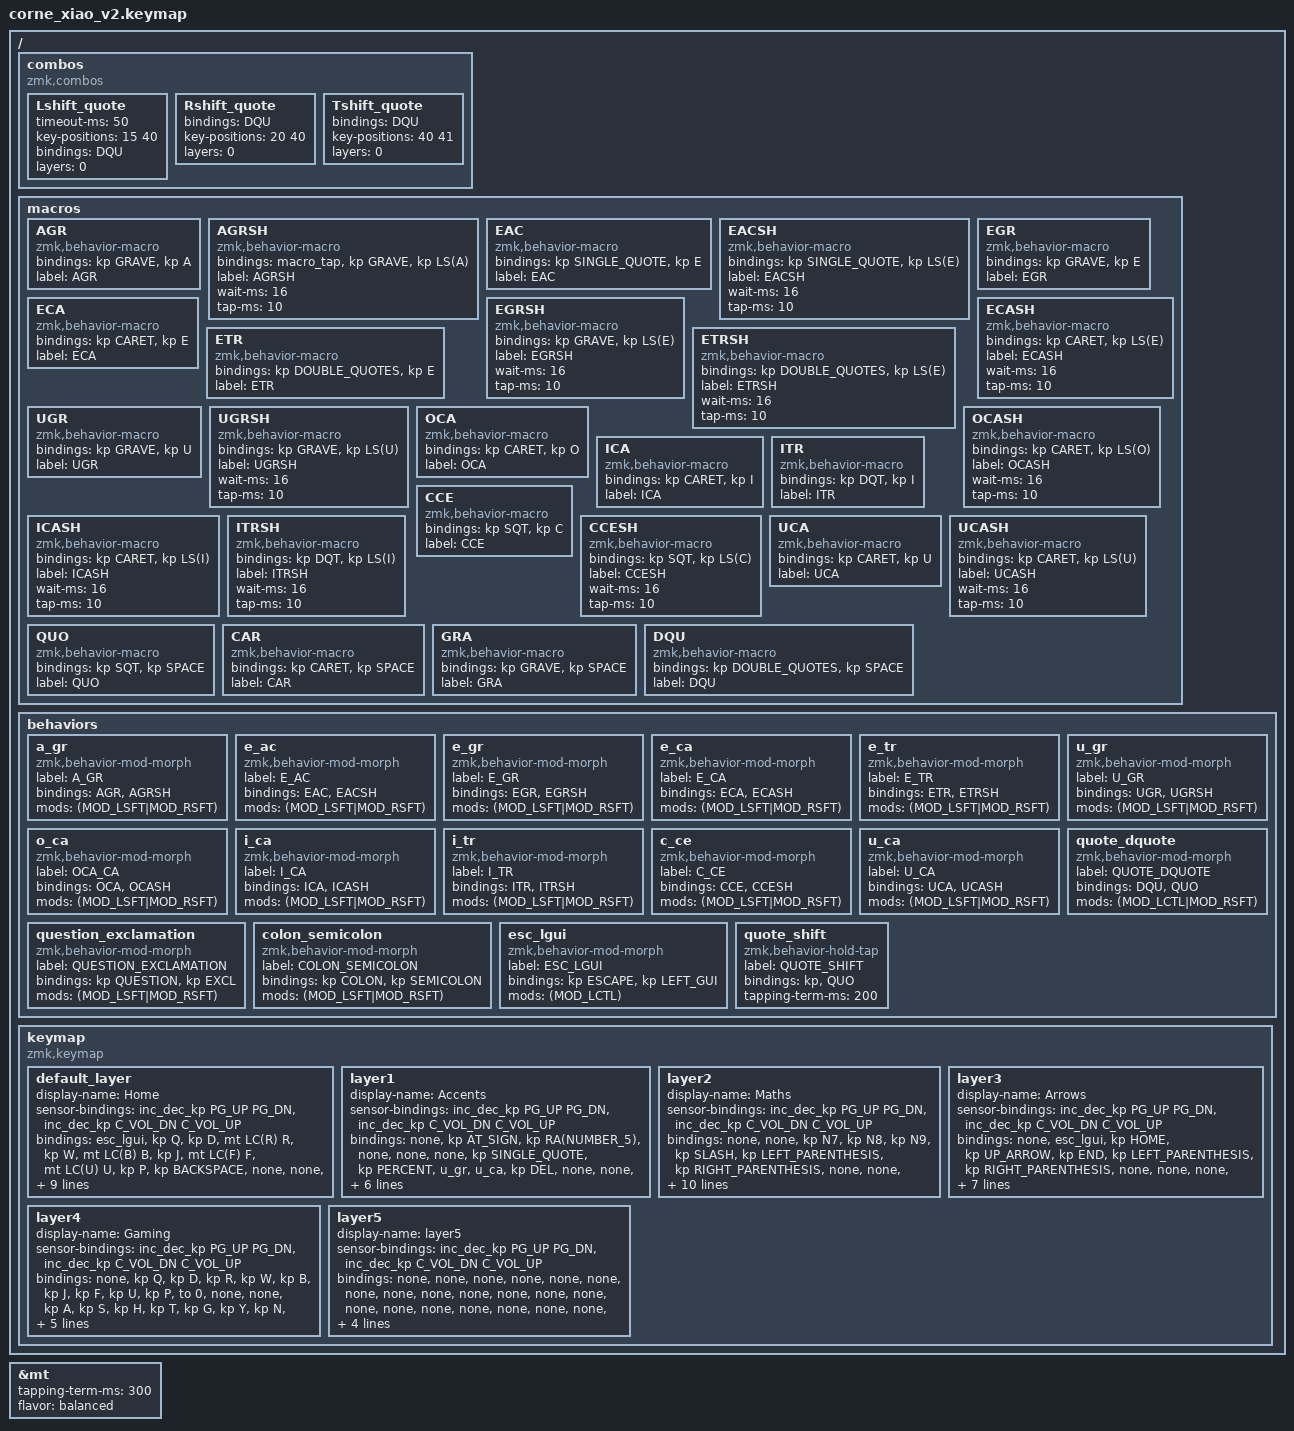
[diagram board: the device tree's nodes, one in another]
#include <behaviors/rgbled_widget.dtsi>  // needed to use the behaviors
#include <behaviors.dtsi>
#include <dt-bindings/zmk/keys.h>

// &ind_bat  indicate battery level
// &ind_con  indicate connectivity status

&mt {
    tapping-term-ms = <300>;
    flavor = "balanced";
};

/ {
    combos {
        compatible = "zmk,combos";

        Lshift_quote {
            timeout-ms = <50>;
            key-positions = <15 40>;
            bindings = <&DQU>;
            layers = <0>;
        };

        Rshift_quote {
            bindings = <&DQU>;
            key-positions = <20 40>;
            layers = <0>;
        };

        Tshift_quote {
            bindings = <&DQU>;
            key-positions = <40 41>;
            layers = <0>;
        };
    };
};

/ {
    macros {
        AGR: AGR {
            compatible = "zmk,behavior-macro";
            #binding-cells = <0>;
            bindings = <&kp GRAVE &kp A>;
            label = "AGR";
        };

        AGRSH: AGRSH {
            compatible = "zmk,behavior-macro";
            #binding-cells = <0>;
            bindings = <&macro_tap>, <&kp GRAVE &kp LS(A)>;

            label = "AGRSH";
            wait-ms = <16>;
            tap-ms = <10>;
        };

        EAC: EAC {
            compatible = "zmk,behavior-macro";
            #binding-cells = <0>;
            bindings = <&kp SINGLE_QUOTE &kp E>;
            label = "EAC";
        };

        EACSH: EACSH {
            compatible = "zmk,behavior-macro";
            #binding-cells = <0>;
            bindings = <&kp SINGLE_QUOTE &kp LS(E)>;
            label = "EACSH";
            wait-ms = <16>;
            tap-ms = <10>;
        };

        EGR: EGR {
            compatible = "zmk,behavior-macro";
            #binding-cells = <0>;
            bindings = <&kp GRAVE &kp E>;
            label = "EGR";
        };

        EGRSH: EGRSH {
            compatible = "zmk,behavior-macro";
            #binding-cells = <0>;
            bindings = <&kp GRAVE &kp LS(E)>;
            label = "EGRSH";
            wait-ms = <16>;
            tap-ms = <10>;
        };

        ECA: ECA {
            compatible = "zmk,behavior-macro";
            #binding-cells = <0>;
            bindings = <&kp CARET &kp E>;
            label = "ECA";
        };

        ECASH: ECASH {
            compatible = "zmk,behavior-macro";
            #binding-cells = <0>;
            bindings = <&kp CARET &kp LS(E)>;
            label = "ECASH";
            wait-ms = <16>;
            tap-ms = <10>;
        };

        ETR: ETR {
            compatible = "zmk,behavior-macro";
            #binding-cells = <0>;
            bindings = <&kp DOUBLE_QUOTES &kp E>;
            label = "ETR";
        };

        ETRSH: ETRSH {
            compatible = "zmk,behavior-macro";
            #binding-cells = <0>;
            bindings = <&kp DOUBLE_QUOTES &kp LS(E)>;
            label = "ETRSH";
            wait-ms = <16>;
            tap-ms = <10>;
        };

        UGR: UGR {
            compatible = "zmk,behavior-macro";
            #binding-cells = <0>;
            bindings = <&kp GRAVE &kp U>;
            label = "UGR";
        };

        UGRSH: UGRSH {
            compatible = "zmk,behavior-macro";
            #binding-cells = <0>;
            bindings = <&kp GRAVE &kp LS(U)>;
            label = "UGRSH";
            wait-ms = <16>;
            tap-ms = <10>;
        };

        OCA: OCA {
            compatible = "zmk,behavior-macro";
            #binding-cells = <0>;
            bindings = <&kp CARET &kp O>;
            label = "OCA";
        };

        OCASH: OCASH {
            compatible = "zmk,behavior-macro";
            #binding-cells = <0>;
            bindings = <&kp CARET &kp LS(O)>;
            label = "OCASH";
            wait-ms = <16>;
            tap-ms = <10>;
        };

        ICA: ICA {
            compatible = "zmk,behavior-macro";
            #binding-cells = <0>;
            bindings = <&kp CARET &kp I>;
            label = "ICA";
        };

        ICASH: ICASH {
            compatible = "zmk,behavior-macro";
            #binding-cells = <0>;
            bindings = <&kp CARET &kp LS(I)>;
            label = "ICASH";
            wait-ms = <16>;
            tap-ms = <10>;
        };

        ITR: ITR {
            compatible = "zmk,behavior-macro";
            #binding-cells = <0>;
            bindings = <&kp DQT &kp I>;
            label = "ITR";
        };

        ITRSH: ITRSH {
            compatible = "zmk,behavior-macro";
            #binding-cells = <0>;
            bindings = <&kp DQT &kp LS(I)>;
            label = "ITRSH";
            wait-ms = <16>;
            tap-ms = <10>;
        };

        CCE: CCE {
            compatible = "zmk,behavior-macro";
            #binding-cells = <0>;
            bindings = <&kp SQT &kp C>;
            label = "CCE";
        };

        CCESH: CCESH {
            compatible = "zmk,behavior-macro";
            #binding-cells = <0>;
            bindings = <&kp SQT &kp LS(C)>;
            label = "CCESH";
            wait-ms = <16>;
            tap-ms = <10>;
        };

        UCA: UCA {
            compatible = "zmk,behavior-macro";
            #binding-cells = <0>;
            bindings = <&kp CARET &kp U>;
            label = "UCA";
        };

        UCASH: UCASH {
            compatible = "zmk,behavior-macro";
            #binding-cells = <0>;
            bindings = <&kp CARET &kp LS(U)>;
            label = "UCASH";
            wait-ms = <16>;
            tap-ms = <10>;
        };

        QUO: QUO {
            compatible = "zmk,behavior-macro";
            #binding-cells = <0>;
            bindings = <&kp SQT &kp SPACE>;
            label = "QUO";
        };

        CAR: CAR {
            compatible = "zmk,behavior-macro";
            #binding-cells = <0>;
            bindings = <&kp CARET &kp SPACE>;
            label = "CAR";
        };

        GRA: GRA {
            compatible = "zmk,behavior-macro";
            #binding-cells = <0>;
            bindings = <&kp GRAVE &kp SPACE>;
            label = "GRA";
        };

        DQU: DQU {
            compatible = "zmk,behavior-macro";
            #binding-cells = <0>;
            bindings = <&kp DOUBLE_QUOTES &kp SPACE>;
            label = "DQU";
        };
    };

    behaviors {
        a_gr: a_gr {
            compatible = "zmk,behavior-mod-morph";
            label = "A_GR";
            bindings = <&AGR>, <&AGRSH>;

            #binding-cells = <0>;
            mods = <(MOD_LSFT|MOD_RSFT)>;
        };

        e_ac: e_ac {
            compatible = "zmk,behavior-mod-morph";
            label = "E_AC";
            bindings = <&EAC>, <&EACSH>;

            #binding-cells = <0>;
            mods = <(MOD_LSFT|MOD_RSFT)>;
        };

        e_gr: e_gr {
            compatible = "zmk,behavior-mod-morph";
            label = "E_GR";
            bindings = <&EGR>, <&EGRSH>;

            #binding-cells = <0>;
            mods = <(MOD_LSFT|MOD_RSFT)>;
        };

        e_ca: e_ca {
            compatible = "zmk,behavior-mod-morph";
            label = "E_CA";
            bindings = <&ECA>, <&ECASH>;

            #binding-cells = <0>;
            mods = <(MOD_LSFT|MOD_RSFT)>;
        };

        e_tr: e_tr {
            compatible = "zmk,behavior-mod-morph";
            label = "E_TR";
            bindings = <&ETR>, <&ETRSH>;

            #binding-cells = <0>;
            mods = <(MOD_LSFT|MOD_RSFT)>;
        };

        u_gr: u_gr {
            compatible = "zmk,behavior-mod-morph";
            label = "U_GR";
            bindings = <&UGR>, <&UGRSH>;

            #binding-cells = <0>;
            mods = <(MOD_LSFT|MOD_RSFT)>;
        };

        o_ca: o_ca {
            compatible = "zmk,behavior-mod-morph";
            label = "OCA_CA";
            bindings = <&OCA>, <&OCASH>;

            #binding-cells = <0>;
            mods = <(MOD_LSFT|MOD_RSFT)>;
        };

        i_ca: i_ca {
            compatible = "zmk,behavior-mod-morph";
            label = "I_CA";
            bindings = <&ICA>, <&ICASH>;

            #binding-cells = <0>;
            mods = <(MOD_LSFT|MOD_RSFT)>;
        };

        i_tr: i_tr {
            compatible = "zmk,behavior-mod-morph";
            label = "I_TR";
            bindings = <&ITR>, <&ITRSH>;

            #binding-cells = <0>;
            mods = <(MOD_LSFT|MOD_RSFT)>;
        };

        c_ce: c_ce {
            compatible = "zmk,behavior-mod-morph";
            label = "C_CE";
            bindings = <&CCE>, <&CCESH>;

            #binding-cells = <0>;
            mods = <(MOD_LSFT|MOD_RSFT)>;
        };

        u_ca: u_ca {
            compatible = "zmk,behavior-mod-morph";
            label = "U_CA";
            bindings = <&UCA>, <&UCASH>;

            #binding-cells = <0>;
            mods = <(MOD_LSFT|MOD_RSFT)>;
        };

        question_exclamation: question_exclamation {
            compatible = "zmk,behavior-mod-morph";
            label = "QUESTION_EXCLAMATION";
            bindings = <&kp QUESTION>, <&kp EXCL>;

            #binding-cells = <0>;
            mods = <(MOD_LSFT|MOD_RSFT)>;
        };

        colon_semicolon: colon_semicolon {
            compatible = "zmk,behavior-mod-morph";
            label = "COLON_SEMICOLON";
            bindings = <&kp COLON>, <&kp SEMICOLON>;

            #binding-cells = <0>;
            mods = <(MOD_LSFT|MOD_RSFT)>;
        };

        esc_lgui: esc_lgui {
            compatible = "zmk,behavior-mod-morph";
            label = "ESC_LGUI";
            bindings = <&kp ESCAPE>, <&kp LEFT_GUI>;

            #binding-cells = <0>;
            mods = <(MOD_LCTL)>;
        };

        quote_dquote: quote_dquote {
            compatible = "zmk,behavior-mod-morph";
            label = "QUOTE_DQUOTE";
            bindings = <&DQU>, <&QUO>;

            #binding-cells = <0>;
            mods = <(MOD_LCTL|MOD_RSFT)>;
        };

        quote_shift: quote_shift {
            compatible = "zmk,behavior-hold-tap";
            label = "QUOTE_SHIFT";
            bindings = <&kp>, <&QUO>;

            #binding-cells = <2>;
            tapping-term-ms = <200>;
        };
    };

    keymap {
        compatible = "zmk,keymap";

        default_layer {
            display-name = "Home";
            sensor-bindings = <&inc_dec_kp PG_UP PG_DN &inc_dec_kp C_VOL_DN C_VOL_UP>;
            bindings = <
&esc_lgui  &kp Q  &kp D  &mt LC(R) R  &kp W  &mt LC(B) B  &kp J  &mt LC(F) F  &mt LC(U) U  &kp P  &kp BACKSPACE  &none  &none  &mt LC(A) A  &mt LC(S) S  &mt LEFT_SHIFT H  &mt LEFT_CONTROL T  &mt G G  &kp Y  &mt LCTRL N  &mt RIGHT_SHIFT E  &kp O  &mt LC(I) I  &question_exclamation  &none  &mt LC(Z) Z  &mt LC(X) X  &kp M  &mt LC(C) C  &mt LC(V) V  &none  &kp C_MUTE  &kp K  &kp L  &kp COMMA  &colon_semicolon  &kp EQUAL  &none  &lt 2 MINUS  &lt 3 SPACE  &quote_shift LEFT_SHIFT 0  &mt LEFT_ALT PERIOD  &kp ENTER  &lt 1 DOT
            >;
        };

        layer1 {
            display-name = "Accents";
            sensor-bindings = <&inc_dec_kp PG_UP PG_DN &inc_dec_kp C_VOL_DN C_VOL_UP>;
            bindings = <
&none  &kp AT_SIGN  &kp RA(NUMBER_5)  &none  &none  &none  &kp SINGLE_QUOTE  &kp PERCENT  &u_gr  &u_ca  &kp DEL  &none  &none  &a_gr  &kp DOLLAR  &kp HASH  &none  &none  &kp CARET  &kp TILDE  &e_ac  &o_ca  &i_ca  &none  &none  &kp AMPERSAND  &none  &none  &c_ce  &none  &none  &none  &kp GRAVE  &e_ca  &e_gr  &e_tr  &i_tr  &none  &none  &none  &none  &none  &none  &none
            >;
        };

        layer2 {
            display-name = "Maths";
            sensor-bindings = <&inc_dec_kp PG_UP PG_DN &inc_dec_kp C_VOL_DN C_VOL_UP>;
            bindings = <
&none  &none  &kp N7  &kp N8  &kp N9  &kp SLASH  &kp LEFT_PARENTHESIS  &kp RIGHT_PARENTHESIS  &none  &none  &kp BACKSPACE  &none  &none  &none  &kp NUMBER_4  &kp N5  &kp NUMBER_6  &kp ASTERISK  &kp LEFT_BRACKET  &kp RIGHT_BRACKET  &kp SLASH  &kp PIPE  &kp NON_US_BACKSLASH  &none  &none  &kp N0  &kp NUMBER_1  &kp NUMBER_2  &kp NUMBER_3  &kp MINUS  &none  &none  &kp LEFT_BRACE  &kp RIGHT_BRACE  &none  &kp TILDE  &none  &none  &none  &kp PLUS  &kp EQUAL  &kp RET  &kp LESS_THAN  &kp GREATER_THAN
            >;
        };

        layer3 {
            display-name = "Arrows";
            sensor-bindings = <&inc_dec_kp PG_UP PG_DN &inc_dec_kp C_VOL_DN C_VOL_UP>;
            bindings = <
&none  &esc_lgui  &kp HOME  &kp UP_ARROW  &kp END  &kp LEFT_PARENTHESIS  &kp RIGHT_PARENTHESIS  &none  &none  &none  &to 4  &none  &none  &kp TAB  &kp LEFT_ARROW  &kp DOWN  &kp RIGHT  &kp QUESTION  &kp EXCL  &kp LCTRL  &kp LEFT_SHIFT  &none  &ind_bat  &none  &none  &kp LEFT_GUI  &kp LC(LEFT_ARROW)  &none  &kp LC(RIGHT)  &none  &none  &none  &none  &none  &none  &none  &none  &none  &none  &trans  &trans  &none  &none  &none
            >;
        };

        layer4 {
            display-name = "Gaming";
            sensor-bindings = <&inc_dec_kp PG_UP PG_DN &inc_dec_kp C_VOL_DN C_VOL_UP>;
            bindings = <
&none  &kp Q  &kp D  &kp R  &kp W  &kp B  &kp J  &kp F  &kp U  &kp P  &to 0  &none  &none  &kp A  &kp S  &kp H  &kp T  &kp G  &kp Y  &kp N  &kp E  &kp O  &kp I  &none  &none  &kp Z  &kp X  &kp M  &kp C  &kp V  &none  &kp ESCAPE  &kp K  &kp L  &kp COMMA  &kp COLON  &kp EQUAL  &none  &kp LEFT_SHIFT  &kp SPACE  &kp MINUS  &kp PERIOD  &kp ENTER  &kp RIGHT_SHIFT
            >;
        };

        layer5 {
            display-name = "layer5";
            sensor-bindings = <&inc_dec_kp PG_UP PG_DN &inc_dec_kp C_VOL_DN C_VOL_UP>;
            bindings = <
&none  &none  &none  &none  &none  &none  &none  &none  &none  &none  &none  &none  &none  &none  &none  &none  &none  &none  &none  &none  &none  &none  &none  &none  &none  &none  &none  &none  &none  &none  &none  &none  &none  &none  &none  &none  &none  &none  &none  &none  &none  &none  &none  &none
            >;
        };
    };
};
